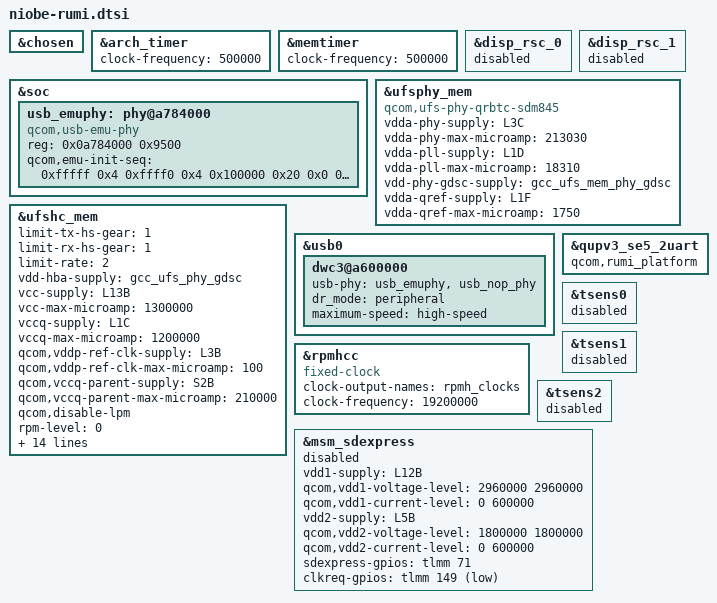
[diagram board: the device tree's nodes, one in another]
#include <dt-bindings/clock/qcom,gcc-niobe.h>
#include <dt-bindings/clock/qcom,rpmh.h>
#include <dt-bindings/gpio/gpio.h>

&chosen {
};

&arch_timer {
	clock-frequency = <500000>;
};

&memtimer {
	clock-frequency = <500000>;
};

&disp_rsc_0 {
	status = "nok";
};

&disp_rsc_1 {
	status = "nok";
};

&soc {
	usb_emuphy: phy@a784000 {
		compatible = "qcom,usb-emu-phy";
		reg = <0x0a784000 0x9500>;

		qcom,emu-init-seq = <0xfffff 0x4
			0xffff0 0x4
			0x100000 0x20
			0x0 0x20
			0x000101F0 0x20
			0x00100000 0x3c
			0x0 0x3c
			0x0 0x4>;
	};
};

&ufsphy_mem {
	compatible = "qcom,ufs-phy-qrbtc-sdm845";

	/* VDDA_UFS_CORE */
	vdda-phy-supply = <&L3C>;
	vdda-phy-max-microamp = <213030>;

	/* VDDA_UFS_0_1P2 */
	vdda-pll-supply = <&L1D>;
	vdda-pll-max-microamp = <18310>;

	/* Phy GDSC for VDD_MX, always on */
	vdd-phy-gdsc-supply = <&gcc_ufs_mem_phy_gdsc>;

	/* Qref power supply, Refer Qref diagram */
	vdda-qref-supply = <&L1F>;
	vdda-qref-max-microamp = <1750>;

	status = "ok";
};

&ufshc_mem {
	limit-tx-hs-gear = <1>;
	limit-rx-hs-gear = <1>;
	limit-rate = <2>; /* HS Rate-B */

	vdd-hba-supply = <&gcc_ufs_phy_gdsc>;

	vcc-supply = <&L13B>;
	vcc-max-microamp = <1300000>;

	vccq-supply = <&L1C>;
	vccq-max-microamp = <1200000>;

	/* VDD_PX10 is voted for the ufs_reset_n */
	qcom,vddp-ref-clk-supply = <&L3B>;
	qcom,vddp-ref-clk-max-microamp = <100>;

	qcom,vccq-parent-supply = <&S2B>;
	qcom,vccq-parent-max-microamp = <210000>;

	qcom,disable-lpm;
	rpm-level = <0>;
	spm-level = <0>;

	qcom,iommu-dma = "bypass";

	clock-names =
		"core_clk",
		"bus_aggr_clk",
		"iface_clk",
		"core_clk_unipro",
		"core_clk_ice",
		"ref_clk",
		"tx_lane0_sync_clk",
		"rx_lane0_sync_clk",
		"rx_lane1_sync_clk";
	clocks =
		<&gcc GCC_UFS_PHY_AXI_CLK>,
		<&gcc GCC_AGGRE_UFS_PHY_AXI_CLK>,
		<&gcc GCC_UFS_PHY_AHB_CLK>,
		<&gcc GCC_UFS_PHY_UNIPRO_CORE_CLK>,
		<&gcc GCC_UFS_PHY_ICE_CORE_CLK>,
		<&rpmhcc RPMH_CXO_PAD_CLK>,
		<&gcc GCC_UFS_PHY_TX_SYMBOL_0_CLK>,
		<&gcc GCC_UFS_PHY_RX_SYMBOL_0_CLK>,
		<&gcc GCC_UFS_PHY_RX_SYMBOL_1_CLK>;
	freq-table-hz =
		<100000000 403000000>,
		<0 0>,
		<0 0>,
		<100000000 403000000>,
		<100000000 403000000>,
		<0 0>,
		<0 0>,
		<0 0>,
		<0 0>;

	status = "ok";
};

&usb0 {
	dwc3@a600000 {
		usb-phy = <&usb_emuphy>, <&usb_nop_phy>;
		dr_mode = "peripheral";
		maximum-speed = "high-speed";
	};
};

&qupv3_se5_2uart {
	qcom,rumi_platform;
};

&rpmhcc {
	compatible = "fixed-clock";
	clock-output-names = "rpmh_clocks";
	clock-frequency = <19200000>;
};

&tsens0 {
	status = "disabled";
};

&tsens1 {
	status = "disabled";
};

&tsens2 {
	status = "disabled";
};

&msm_sdexpress {
	vdd1-supply = <&L12B>;
	qcom,vdd1-voltage-level = <2960000 2960000>;
	qcom,vdd1-current-level = <0 600000>;

	vdd2-supply = <&L5B>;
	qcom,vdd2-voltage-level = <1800000 1800000>;
	qcom,vdd2-current-level = <0 600000>;

	sdexpress-gpios = <&tlmm 71 0>;
	clkreq-gpios = <&tlmm 149 GPIO_ACTIVE_LOW>;

	status = "disabled";
};
